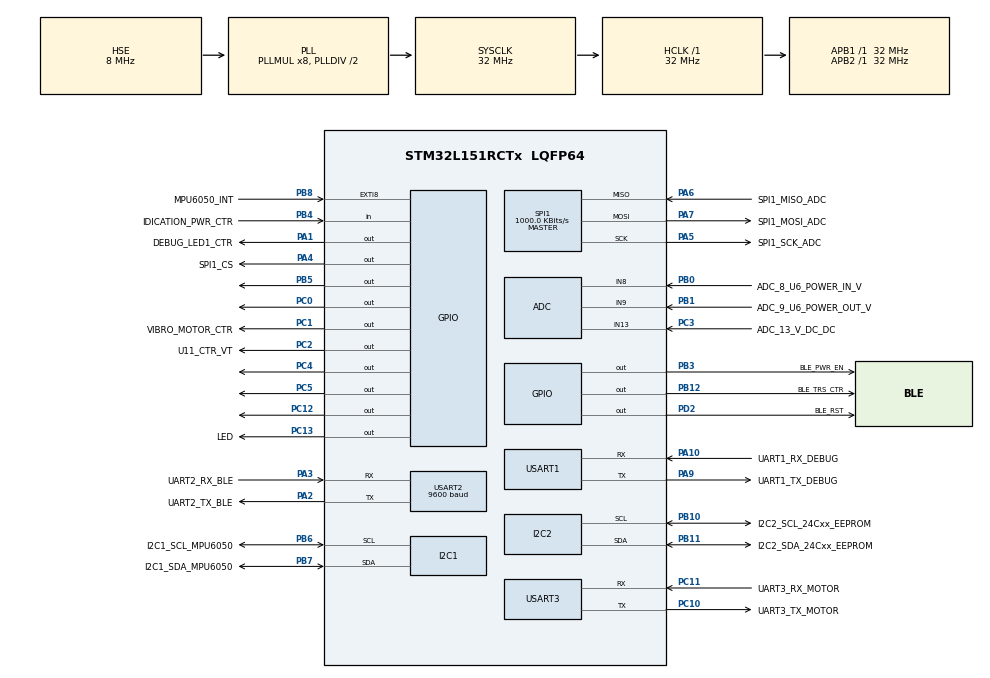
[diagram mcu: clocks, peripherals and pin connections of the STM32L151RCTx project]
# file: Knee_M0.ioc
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ADC.Channel-0\#ChannelRegularConversion=ADC_CHANNEL_13
ADC.NbrOfConversionFlag=1
ADC.Rank-0\#ChannelRegularConversion=1
ADC.SamplingTime-0\#ChannelRegularConversion=ADC_SAMPLETIME_4CYCLES
Dma.Request0=USART1_TX
Dma.Request1=USART2_RX
Dma.Request2=USART2_TX
Dma.Request3=USART3_RX
Dma.Request4=USART3_TX
Dma.Request5=USART1_RX
Dma.USART1_RX.5.Direction=DMA_PERIPH_TO_MEMORY
Dma.USART1_RX.5.Instance=DMA1_Channel5
Dma.USART1_RX.5.MemDataAlignment=DMA_MDATAALIGN_BYTE
Dma.USART1_RX.5.MemInc=DMA_MINC_ENABLE
Dma.USART1_RX.5.Mode=DMA_NORMAL
Dma.USART1_RX.5.PeriphDataAlignment=DMA_PDATAALIGN_BYTE
Dma.USART1_RX.5.PeriphInc=DMA_PINC_DISABLE
Dma.USART1_RX.5.Priority=DMA_PRIORITY_LOW
Dma.USART1_TX.0.Direction=DMA_MEMORY_TO_PERIPH
Dma.USART1_TX.0.Instance=DMA1_Channel4
Dma.USART1_TX.0.MemDataAlignment=DMA_MDATAALIGN_BYTE
Dma.USART1_TX.0.MemInc=DMA_MINC_ENABLE
Dma.USART1_TX.0.Mode=DMA_NORMAL
Dma.USART1_TX.0.PeriphDataAlignment=DMA_PDATAALIGN_BYTE
Dma.USART1_TX.0.PeriphInc=DMA_PINC_DISABLE
Dma.USART1_TX.0.Priority=DMA_PRIORITY_LOW
Dma.USART2_RX.1.Direction=DMA_PERIPH_TO_MEMORY
Dma.USART2_RX.1.Instance=DMA1_Channel6
Dma.USART2_RX.1.MemDataAlignment=DMA_MDATAALIGN_BYTE
Dma.USART2_RX.1.MemInc=DMA_MINC_ENABLE
Dma.USART2_RX.1.Mode=DMA_NORMAL
Dma.USART2_RX.1.PeriphDataAlignment=DMA_PDATAALIGN_BYTE
Dma.USART2_RX.1.PeriphInc=DMA_PINC_DISABLE
Dma.USART2_RX.1.Priority=DMA_PRIORITY_LOW
Dma.USART2_TX.2.Direction=DMA_MEMORY_TO_PERIPH
Dma.USART2_TX.2.Instance=DMA1_Channel7
Dma.USART2_TX.2.MemDataAlignment=DMA_MDATAALIGN_BYTE
Dma.USART2_TX.2.MemInc=DMA_MINC_ENABLE
Dma.USART2_TX.2.Mode=DMA_NORMAL
Dma.USART2_TX.2.PeriphDataAlignment=DMA_PDATAALIGN_BYTE
Dma.USART2_TX.2.PeriphInc=DMA_PINC_DISABLE
Dma.USART2_TX.2.Priority=DMA_PRIORITY_LOW
Dma.USART3_RX.3.Direction=DMA_PERIPH_TO_MEMORY
Dma.USART3_RX.3.Instance=DMA1_Channel3
Dma.USART3_RX.3.MemDataAlignment=DMA_MDATAALIGN_BYTE
Dma.USART3_RX.3.MemInc=DMA_MINC_ENABLE
Dma.USART3_RX.3.Mode=DMA_NORMAL
Dma.USART3_RX.3.PeriphDataAlignment=DMA_PDATAALIGN_BYTE
Dma.USART3_RX.3.PeriphInc=DMA_PINC_DISABLE
Dma.USART3_RX.3.Priority=DMA_PRIORITY_LOW
Dma.USART3_TX.4.Direction=DMA_MEMORY_TO_PERIPH
Dma.USART3_TX.4.Instance=DMA1_Channel2
Dma.USART3_TX.4.MemDataAlignment=DMA_MDATAALIGN_BYTE
Dma.USART3_TX.4.MemInc=DMA_MINC_ENABLE
Dma.USART3_TX.4.Mode=DMA_NORMAL
Dma.USART3_TX.4.PeriphDataAlignment=DMA_PDATAALIGN_BYTE
Dma.USART3_TX.4.PeriphInc=DMA_PINC_DISABLE
Dma.USART3_TX.4.Priority=DMA_PRIORITY_LOW
I2C1.I2C_Mode=I2C_Fast
I2C2.I2C_Mode=I2C_Fast
Mcu.Family=STM32L1
Mcu.Name=STM32L151RCTx
Mcu.Package=LQFP64
NVIC.DMA1_Channel2_IRQn=true\:0\:0\:false\:false\:true\:false\:true
NVIC.DMA1_Channel3_IRQn=true\:0\:0\:false\:false\:true\:false\:true
NVIC.DMA1_Channel4_IRQn=true\:0\:0\:false\:false\:true\:false\:true
NVIC.DMA1_Channel5_IRQn=true\:0\:0\:false\:false\:true\:false\:true
NVIC.DMA1_Channel6_IRQn=true\:0\:0\:false\:false\:true\:false\:true
NVIC.DMA1_Channel7_IRQn=true\:0\:0\:false\:false\:true\:false\:true
NVIC.PriorityGroup=NVIC_PRIORITYGROUP_4
PA1.GPIO_Label=DEBUG_LED1_CTR
PA1.Signal=GPIO_Output
PA10.GPIO_Label=UART1_RX_DEBUG
PA10.Mode=Asynchronous
PA10.Signal=USART1_RX
PA13.Mode=Serial_Wire
PA13.Signal=SYS_JTMS-SWDIO
PA14.Mode=Serial_Wire
PA14.Signal=SYS_JTCK-SWCLK
PA2.GPIO_Label=UART2_TX_BLE
PA2.Mode=Asynchronous
PA2.Signal=USART2_TX
PA3.GPIO_Label=UART2_RX_BLE
PA3.Mode=Asynchronous
PA3.Signal=USART2_RX
PA4.GPIO_Label=SPI1_CS
PA4.Signal=GPIO_Output
PA5.GPIO_Label=SPI1_SCK_ADC
PA5.Mode=Full_Duplex_Master
PA5.Signal=SPI1_SCK
PA6.GPIO_Label=SPI1_MISO_ADC
PA6.Mode=Full_Duplex_Master
PA6.Signal=SPI1_MISO
PA7.GPIO_Label=SPI1_MOSI_ADC
PA7.Mode=Full_Duplex_Master
PA7.Signal=SPI1_MOSI
PA9.GPIO_Label=UART1_TX_DEBUG
PA9.Mode=Asynchronous
PA9.Signal=USART1_TX
PB0.GPIO_Label=ADC_8_U6_POWER_IN_V
PB0.Mode=IN8
PB0.Signal=ADC_IN8
PB1.GPIO_Label=ADC_9_U6_POWER_OUT_V
PB1.Mode=IN9
PB1.Signal=ADC_IN9
PB10.GPIO_Label=I2C2_SCL_24Cxx_EEPROM
PB10.GPIO_Pu=GPIO_PULLUP
PB10.Mode=I2C
PB10.Signal=I2C2_SCL
PB11.GPIO_Label=I2C2_SDA_24Cxx_EEPROM
PB11.GPIO_Pu=GPIO_PULLUP
PB11.Mode=I2C
PB11.Signal=I2C2_SDA
PB12.GPIO_Label=BLE_TRS_CTR
PB12.PinState=GPIO_PIN_SET
PB12.Signal=GPIO_Output
PB3.GPIO_Label=BLE_PWR_EN
PB3.Signal=GPIO_Output
PB4.GPIO_Label=IDICATION_PWR_CTR
PB4.Signal=GPIO_Input
PB5.Signal=GPIO_Output
PB6.GPIO_Label=I2C1_SCL_MPU6050
PB6.GPIO_Pu=GPIO_PULLUP
PB6.Mode=I2C
PB6.Signal=I2C1_SCL
PB7.GPIO_Label=I2C1_SDA_MPU6050
PB7.GPIO_Pu=GPIO_PULLUP
PB7.Mode=I2C
PB7.Signal=I2C1_SDA
PB8.GPIO_Label=MPU6050_INT
PB8.GPIO_ModeDefaultEXTI=GPIO_MODE_IT_RISING_FALLING
PB8.Signal=GPXTI8
PC0.Signal=GPIO_Output
PC1.GPIO_Label=VIBRO_MOTOR_CTR
PC1.PinState=GPIO_PIN_SET
PC1.Signal=GPIO_Output
PC10.GPIO_Label=UART3_TX_MOTOR
PC10.Mode=Asynchronous
PC10.Signal=USART3_TX
PC11.GPIO_Label=UART3_RX_MOTOR
PC11.Mode=Asynchronous
PC11.Signal=USART3_RX
PC12.Signal=GPIO_Output
PC13-WKUP2.GPIO_Label=LED
PC13-WKUP2.PinState=GPIO_PIN_SET
PC13-WKUP2.Signal=GPIO_Output
PC2.GPIO_Label=U11_CTR_VT
PC2.PinState=GPIO_PIN_SET
PC2.Signal=GPIO_Output
PC3.GPIO_Label=ADC_13_V_DC_DC
PC3.Mode=IN13
PC3.Signal=ADC_IN13
PC4.PinState=GPIO_PIN_RESET
PC4.Signal=GPIO_Output
PC5.PinState=GPIO_PIN_SET
PC5.Signal=GPIO_Output
PD2.GPIO_Label=BLE_RST
PD2.Signal=GPIO_Output
PH0-OSC_IN.Mode=HSE-External-Oscillator
PH0-OSC_IN.Signal=RCC_OSC_IN
PH1-OSC_OUT.Mode=HSE-External-Oscillator
PH1-OSC_OUT.Signal=RCC_OSC_OUT
ProjectManager.HeapSize=0x200
ProjectManager.StackSize=0x400
ProjectManager.TargetToolchain=STM32CubeIDE
RCC.48MHZClocksFreq_Value=32000000
RCC.AHBFreq_Value=32000000
RCC.APB1Freq_Value=32000000
RCC.APB1TimFreq_Value=32000000
RCC.APB2Freq_Value=32000000
RCC.APB2TimFreq_Value=32000000
RCC.HCLKFreq_Value=32000000
RCC.HSE_VALUE=8000000
RCC.HSI_VALUE=16000000
RCC.LSE_VALUE=32768
RCC.MSI_VALUE=2097000
RCC.PLLMUL=RCC_PLL_MUL8
RCC.PLLSourceVirtual=RCC_PLLSOURCE_HSE
RCC.SYSCLKFreq_VALUE=32000000
RCC.SYSCLKSource=RCC_SYSCLKSOURCE_PLLCLK
RCC.VCOOutputFreq_Value=64000000
SPI1.BaudRatePrescaler=SPI_BAUDRATEPRESCALER_32
SPI1.CalculateBaudRate=1000.0 KBits/s
SPI1.Direction=SPI_DIRECTION_2LINES
SPI1.Mode=SPI_MODE_MASTER
SPI1.VirtualType=VM_MASTER
USART1.VirtualMode=VM_ASYNC
USART2.BaudRate=9600
USART2.VirtualMode=VM_ASYNC
USART3.VirtualMode=VM_ASYNC
VP_TIM2_VS_ClockSourceINT.Mode=Internal
VP_TIM3_VS_ClockSourceINT.Mode=Internal
VP_WWDG_VS_WWDG.Mode=WWDG_Activate
board=custom

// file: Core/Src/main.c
/* USER CODE BEGIN Header */
/**
  ******************************************************************************
  * @file           : main.c
  * @brief          : Main program body
  ******************************************************************************
  * @attention
  *
  * Copyright (c) 2026 STMicroelectronics.
  * All rights reserved.
  *
  * This software is licensed under terms that can be found in the LICENSE file
  * in the root directory of this software component.
  * If no LICENSE file comes with this software, it is provided AS-IS.
  *
  ******************************************************************************
  */
/* USER CODE END Header */
#include "main.h"
#include "adc.h"
#include "dma.h"
#include "i2c.h"
#include "spi.h"
#include "tim.h"
#include "usart.h"
#include "wwdg.h"
#include "gpio.h"

/* USER CODE BEGIN Includes */
#include "app/app.h"

/* USER CODE END Includes */

void SystemClock_Config(void);

int main(void)
{

  /* MCU Configuration--------------------------------------------------------*/

  /* Reset of all peripherals, Initializes the Flash interface and the Systick. */
  HAL_Init();

  /* Configure the system clock */
  SystemClock_Config();

  /* Initialize all configured peripherals */
  MX_GPIO_Init();
  MX_DMA_Init();
  MX_USART1_UART_Init();
  MX_USART2_UART_Init();
  MX_USART3_UART_Init();
  MX_ADC_Init();
  MX_I2C1_Init();
  MX_I2C2_Init();
  MX_SPI1_Init();
  MX_TIM2_Init();
  MX_TIM3_Init();
 // MX_WWDG_Init();
  /* USER CODE BEGIN 2 */
  HAL_GPIO_WritePin(GPIOC, VIBRO_MOTOR_CTR_Pin, GPIO_PIN_RESET);
  App_Init();

  /* USER CODE END 2 */

  /* Infinite loop */
  while (1)
  {

    /* USER CODE BEGIN 3 */
    App_Loop();
  }
  /* USER CODE END 3 */
}

void SystemClock_Config(void)
{
  RCC_OscInitTypeDef RCC_OscInitStruct = {0};
  RCC_ClkInitTypeDef RCC_ClkInitStruct = {0};

  /** Configure the main internal regulator output voltage
  */
  __HAL_PWR_VOLTAGESCALING_CONFIG(PWR_REGULATOR_VOLTAGE_SCALE1);
  /** Initializes the RCC Oscillators according to the specified parameters
  * in the RCC_OscInitTypeDef structure.
  */
  RCC_OscInitStruct.OscillatorType = RCC_OSCILLATORTYPE_HSI|RCC_OSCILLATORTYPE_HSE;
  RCC_OscInitStruct.HSEState = RCC_HSE_ON;
  RCC_OscInitStruct.HSIState = RCC_HSI_ON;
  RCC_OscInitStruct.HSICalibrationValue = RCC_HSICALIBRATION_DEFAULT;
  RCC_OscInitStruct.PLL.PLLState = RCC_PLL_ON;
  RCC_OscInitStruct.PLL.PLLSource = RCC_PLLSOURCE_HSE;
  RCC_OscInitStruct.PLL.PLLMUL = RCC_PLL_MUL8;
  RCC_OscInitStruct.PLL.PLLDIV = RCC_PLL_DIV2;
  if (HAL_RCC_OscConfig(&RCC_OscInitStruct) != HAL_OK)
  {
    Error_Handler();
  }
  /** Initializes the CPU, AHB and APB buses clocks
  */
  RCC_ClkInitStruct.ClockType = RCC_CLOCKTYPE_HCLK|RCC_CLOCKTYPE_SYSCLK
                              |RCC_CLOCKTYPE_PCLK1|RCC_CLOCKTYPE_PCLK2;
  RCC_ClkInitStruct.SYSCLKSource = RCC_SYSCLKSOURCE_PLLCLK;
  RCC_ClkInitStruct.AHBCLKDivider = RCC_SYSCLK_DIV1;
  RCC_ClkInitStruct.APB1CLKDivider = RCC_HCLK_DIV1;
  RCC_ClkInitStruct.APB2CLKDivider = RCC_HCLK_DIV1;

  if (HAL_RCC_ClockConfig(&RCC_ClkInitStruct, FLASH_LATENCY_1) != HAL_OK)
  {
    Error_Handler();
  }
}

void Error_Handler(void)
{
  __disable_irq();
  while (1)
  {
  }
}
